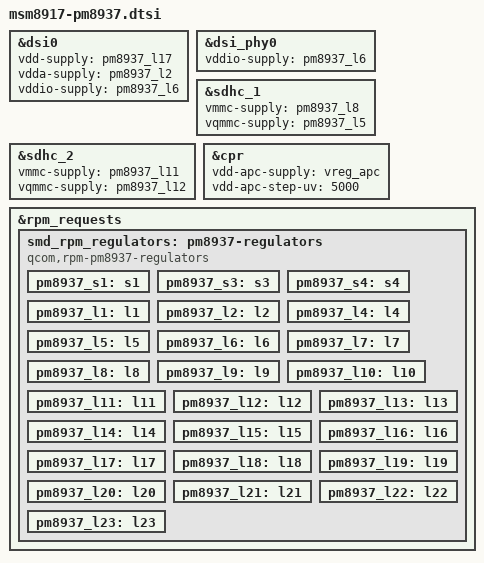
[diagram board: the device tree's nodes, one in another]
// SPDX-License-Identifier: GPL-2.0-only
#include "msm8917.dtsi"
#include "pm8937.dtsi"

&dsi0 {
	vdd-supply = <&pm8937_l17>;
	vdda-supply = <&pm8937_l2>;
	vddio-supply = <&pm8937_l6>;
};

&dsi_phy0 {
	vddio-supply = <&pm8937_l6>;
};

&sdhc_1 {
	vmmc-supply = <&pm8937_l8>;
	vqmmc-supply = <&pm8937_l5>;
};

&sdhc_2 {
	vmmc-supply = <&pm8937_l11>;
	vqmmc-supply = <&pm8937_l12>;
};

&cpr {
	vdd-apc-supply = <&vreg_apc>;
	vdd-apc-step-uv = <5000>;
};

&rpm_requests {
	smd_rpm_regulators: pm8937-regulators {
		compatible = "qcom,rpm-pm8937-regulators";
		/* comments made by flto */
		pm8937_s1: s1 {}; /* MSM modem */
		/* pm8937_s2 is managed by rpmpd (MSM8937_VDDCX) */
		pm8937_s3: s3 {};
		pm8937_s4: s4 {};
		/* pm8937_5 and s6 is SPM regulator used by CPU */
		pm8937_l1: l1 {}; /* RFICs */
		pm8937_l2: l2 {}; /* LPDDR2/LPDDR3, MIPI CSI, and DSI */
		/* pm8937_l3 is managed by rpmpd (MSM8937_VDDMX) */
		pm8937_l4: l4 {};
		pm8937_l5: l5 {}; /* Most digital I/Os, MSM pad groups 3 and 7, LPDDR, and eMMC */
		pm8937_l6: l6 {}; /* MSM DSI PLL and OTP, camera, touchscreen, display, and sensors */
		pm8937_l7: l7 {}; /* MSM analog and PLLs, WCN XO, and PM baseband clock driver */
		pm8937_l8: l8 {}; /* eMMC */
		pm8937_l9: l9 {}; /* WCN */
		pm8937_l10: l10 {}; /* Sensors */
		pm8937_l11: l11 {}; /* Micro SD */
		pm8937_l12: l12 {}; /* MSM pad group 2 and SDC2 */
		pm8937_l13: l13 {}; /* MSM USB and audio */
		pm8937_l14: l14 {}; /* MSM pad group 5, dual-voltage UIM1, and NFC */
		pm8937_l15: l15 {}; /* MSM pad group 6 and dual-voltage UIM2 */
		pm8937_l16: l16 {}; /* PMIC HKADC */
		pm8937_l17: l17 {}; /* Camera, display, and touchscreen */
		pm8937_l18: l18 {}; /* QTI RF front-end */
		pm8937_l19: l19 {}; /* MSM analog, WCN, and WGR */
		pm8937_l20: l20 {}; /* PMIC XO circuits */
		pm8937_l21: l21 {}; /* PMIC RF clock buffers */
		pm8937_l22: l22 {}; /* Camera - analog */
		pm8937_l23: l23 {}; /* Camera - digital */
	};
};
